# HC32M441 register map
File version: 1.0
CPU: CM4 r0p1, little endian, MPU, FPU, 4 interrupt priority bits
Registers are 32-bit, read-write, reset 0x0 unless marked. A register's access mark holds for its fields unless they carry their own. Offsets are from the block's base; [hi:lo] are bit positions; {n}, {i} and the like mark numbered series.

## I2C1 — desc I2C
Base 0x4003B400
Same registers: I2C2 0x4003B800
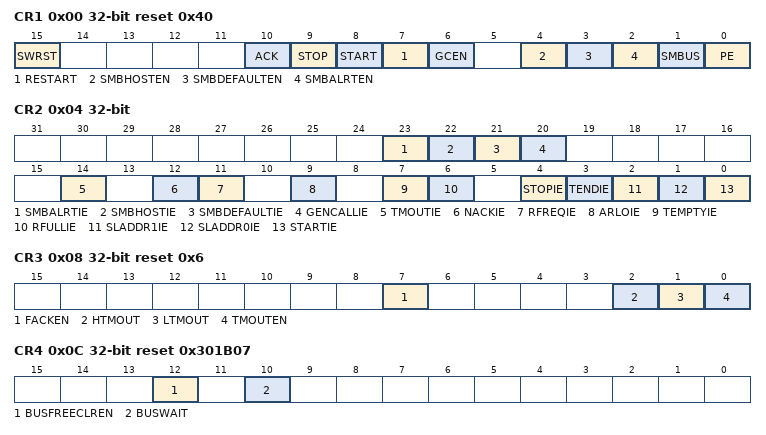
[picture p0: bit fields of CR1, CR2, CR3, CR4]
0x00 CR1 reset 0x40
  [15] SWRST, [10] ACK, [9] STOP, [8] START, [7] RESTART, [6] GCEN, [4] SMBHOSTEN, [3] SMBDEFAULTEN, [2] SMBALRTEN, [1] SMBUS, [0] PE
0x04 CR2
  [23] SMBALRTIE, [22] SMBHOSTIE, [21] SMBDEFAULTIE, [20] GENCALLIE, [14] TMOUTIE, [12] NACKIE, [11] RFREQIE, [9] ARLOIE, [7] TEMPTYIE, [6] RFULLIE, [4] STOPIE, [3] TENDIE, [2] SLADDR1IE, [1] SLADDR0IE, [0] STARTIE
0x08 CR3 reset 0x6
  [7] FACKEN, [2] HTMOUT, [1] LTMOUT, [0] TMOUTEN
0x0C CR4 reset 0x301B07
  [12] BUSFREECLREN, [10] BUSWAIT
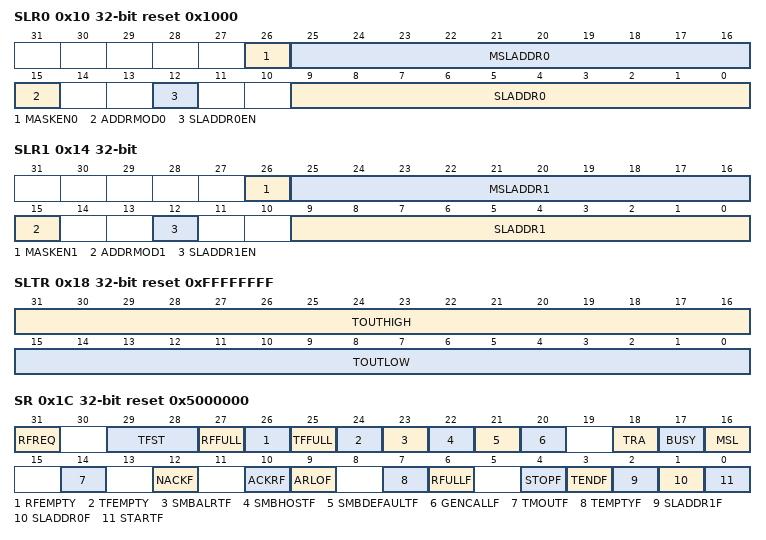
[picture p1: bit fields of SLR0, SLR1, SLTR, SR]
0x10 SLR0 reset 0x1000
  [26] MASKEN0, [25:16] MSLADDR0, [15] ADDRMOD0, [12] SLADDR0EN, [9:0] SLADDR0
0x14 SLR1
  [26] MASKEN1, [25:16] MSLADDR1, [15] ADDRMOD1, [12] SLADDR1EN, [9:0] SLADDR1
0x18 SLTR reset 0xFFFFFFFF
  [31:16] TOUTHIGH, [15:0] TOUTLOW
0x1C SR reset 0x5000000
  [31] RFREQ, [29:28] TFST, [27] RFFULL, [26] RFEMPTY, [25] TFFULL, [24] TFEMPTY, [23] SMBALRTF, [22] SMBHOSTF, [21] SMBDEFAULTF, [20] GENCALLF, [18] TRA, [17] BUSY, [16] MSL, [14] TMOUTF, [12] NACKF, [10] ACKRF, [9] ARLOF, [7] TEMPTYF, [6] RFULLF, [4] STOPF, [3] TENDF, [2] SLADDR1F, [1] SLADDR0F, [0] STARTF
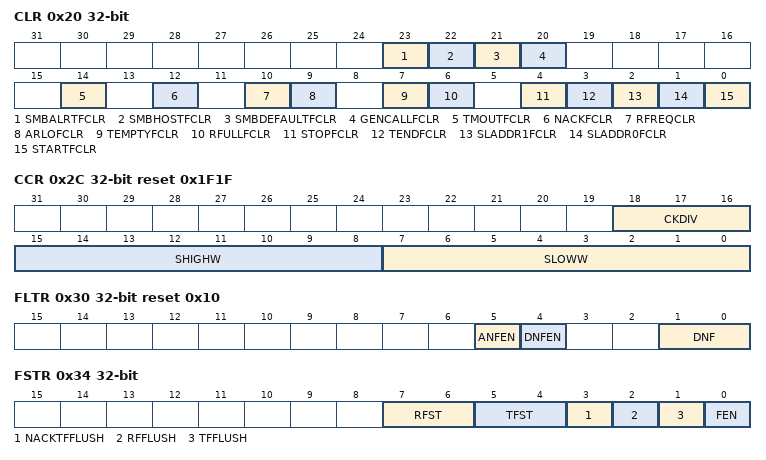
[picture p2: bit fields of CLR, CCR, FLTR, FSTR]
0x20 CLR wo
  [23] SMBALRTFCLR, [22] SMBHOSTFCLR, [21] SMBDEFAULTFCLR, [20] GENCALLFCLR, [14] TMOUTFCLR, [12] NACKFCLR, [10] RFREQCLR, [9] ARLOFCLR, [7] TEMPTYFCLR, [6] RFULLFCLR, [4] STOPFCLR, [3] TENDFCLR, [2] SLADDR1FCLR, [1] SLADDR0FCLR, [0] STARTFCLR
0x24 DTR 8-bit wo reset 0xFF
  [7:0] DT
0x28 DRR 8-bit ro
  [7:0] DR
0x2C CCR reset 0x1F1F
  [18:16] CKDIV, [15:8] SHIGHW, [7:0] SLOWW
0x30 FLTR reset 0x10
  [5] ANFEN, [4] DNFEN, [1:0] DNF
0x34 FSTR
  [7:6] RFST, [5:4] TFST, [3] NACKTFFLUSH, [2] RFFLUSH, [1] TFFLUSH, [0] FEN
0x38 SLVADDR
  [9:0] SLVADRR

## ICG
Base 0x00000400
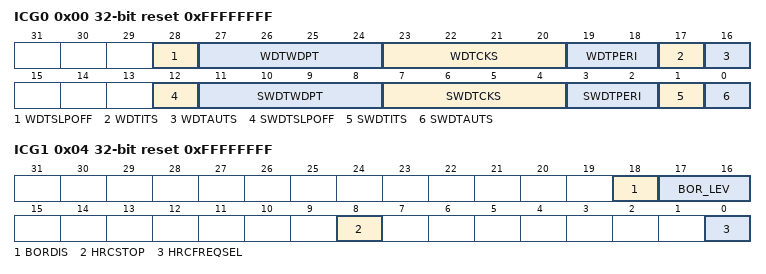
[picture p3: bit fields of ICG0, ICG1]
0x00 ICG0 ro reset 0xFFFFFFFF
  [28] WDTSLPOFF, [27:24] WDTWDPT, [23:20] WDTCKS, [19:18] WDTPERI, [17] WDTITS, [16] WDTAUTS, [12] SWDTSLPOFF, [11:8] SWDTWDPT, [7:4] SWDTCKS, [3:2] SWDTPERI, [1] SWDTITS, [0] SWDTAUTS
0x04 ICG1 ro reset 0xFFFFFFFF
  [18] BORDIS, [17:16] BOR_LEV, [8] HRCSTOP, [0] HRCFREQSEL
0x0C ICG3 ro reset 0xFFFFFFFF
  [15:0] DBUSPRT
0x10 ICG4 ro reset 0xFFFFFFFF

## INTC
Base 0x40051000
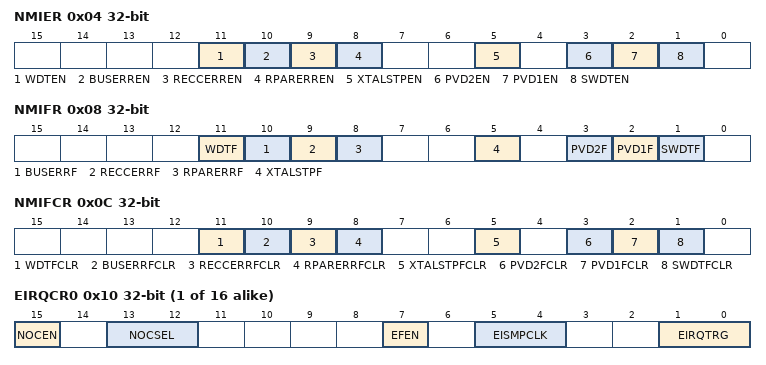
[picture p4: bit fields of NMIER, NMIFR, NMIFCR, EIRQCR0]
0x04 NMIER
  [11] WDTEN, [10] BUSERREN, [9] RECCERREN, [8] RPARERREN, [5] XTALSTPEN, [3] PVD2EN, [2] PVD1EN, [1] SWDTEN
0x08 NMIFR
  [11] WDTF, [10] BUSERRF, [9] RECCERRF, [8] RPARERRF, [5] XTALSTPF, [3] PVD2F, [2] PVD1F, [1] SWDTF
0x0C NMIFCR
  [11] WDTFCLR, [10] BUSERRFCLR, [9] RECCERRFCLR, [8] RPARERRFCLR, [5] XTALSTPFCLR, [3] PVD2FCLR, [2] PVD1FCLR, [1] SWDTFCLR
{0x10+4i} EIRQCR{i} (i=0..15)
  [15] NOCEN, [13:12] NOCSEL, [7] EFEN, [5:4] EISMPCLK, [1:0] EIRQTRG
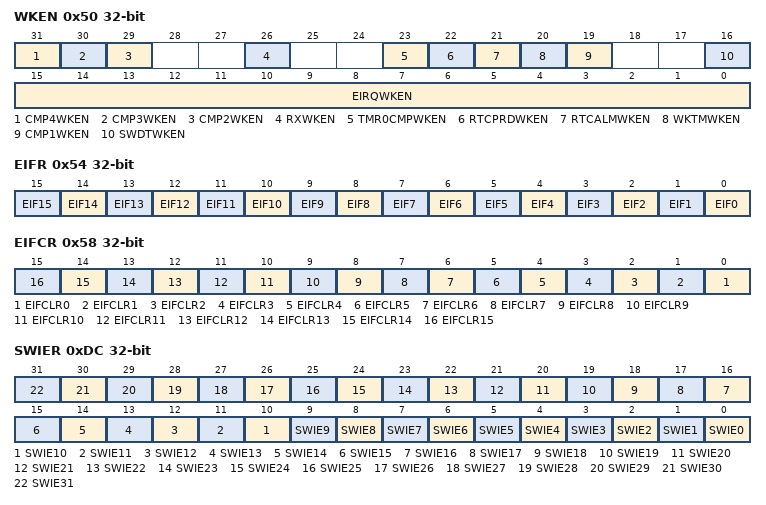
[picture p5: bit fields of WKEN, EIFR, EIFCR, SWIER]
0x50 WKEN
  [31] CMP4WKEN, [30] CMP3WKEN, [29] CMP2WKEN, [26] RXWKEN, [23] TMR0CMPWKEN, [22] RTCPRDWKEN, [21] RTCALMWKEN, [20] WKTMWKEN, [19] CMP1WKEN, [16] SWDTWKEN, [15:0] EIRQWKEN
0x54 EIFR
  [n] EIF{n} (n=0..15)
0x58 EIFCR
  [n] EIFCLR{n} (n=0..15)
{0x5C+4i} INTSEL{i} reset 0x1FF (i=0..15)
  [8:0] INTSEL
{0x9C+4i} INTEN{i} reset 0xFFFFFFFF (i=0..15)
  [31:0] INTEN
0xDC SWIER
  [n] SWIE{n} (n=0..31)
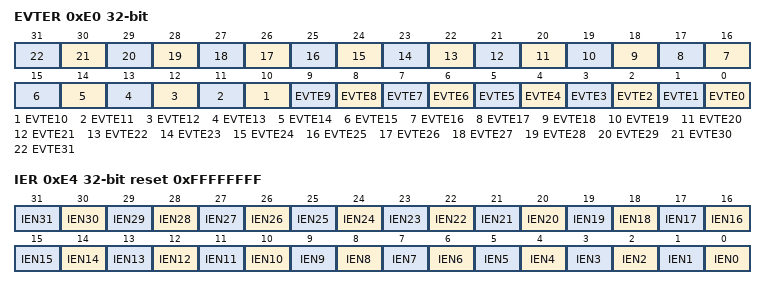
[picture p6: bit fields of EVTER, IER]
0xE0 EVTER
  [n] EVTE{n} (n=0..31)
0xE4 IER reset 0xFFFFFFFF
  [n] IEN{n} (n=0..31)

## KEYSCAN
Base 0x40050C00
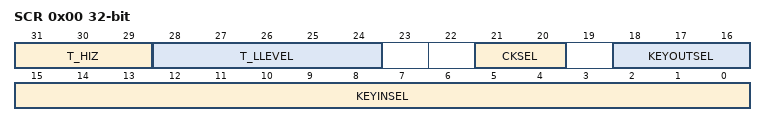
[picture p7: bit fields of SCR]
0x00 SCR
  [31:29] T_HIZ, [28:24] T_LLEVEL, [21:20] CKSEL, [18:16] KEYOUTSEL, [15:0] KEYINSEL
0x04 SER
  [0] SEN
0x08 SSR
  [2:0] INDEX

## MPU
Base 0x40050000
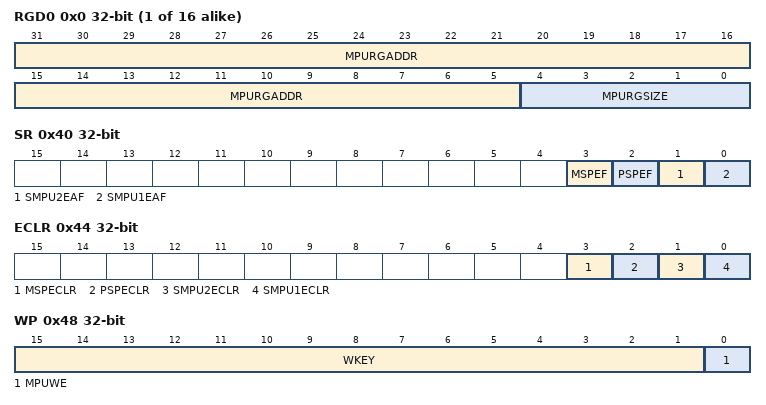
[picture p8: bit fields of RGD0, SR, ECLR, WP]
{0x0+4i} RGD{i} (i=0..15)
  [31:5] MPURGADDR, [4:0] MPURGSIZE
0x40 SR ro
  [3] MSPEF, [2] PSPEF, [1] SMPU2EAF, [0] SMPU1EAF
0x44 ECLR wo
  [3] MSPECLR, [2] PSPECLR, [1] SMPU2ECLR, [0] SMPU1ECLR
0x48 WP
  [15:1] WKEY, [0] MPUWE
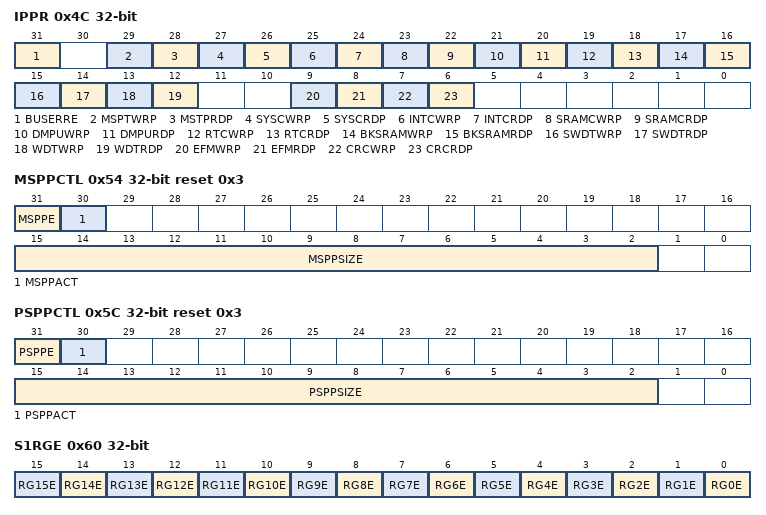
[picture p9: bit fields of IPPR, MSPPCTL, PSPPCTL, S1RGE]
0x4C IPPR (reset mask 0xBFFFF3A0)
  [31] BUSERRE, [29] MSPTWRP, [28] MSTPRDP, [27] SYSCWRP, [26] SYSCRDP, [25] INTCWRP, [24] INTCRDP, [23] SRAMCWRP, [22] SRAMCRDP, [21] DMPUWRP, [20] DMPURDP, [19] RTCWRP, [18] RTCRDP, [17] BKSRAMWRP, [16] BKSRAMRDP, [15] SWDTWRP, [14] SWDTRDP, [13] WDTWRP, [12] WDTRDP, [9] EFMWRP, [8] EFMRDP, [7] CRCWRP, [6] CRCRDP
0x50 MSPPBA
  [31:2] MSPPBA
0x54 MSPPCTL reset 0x3
  [31] MSPPE, [30] MSPPACT, [15:2] MSPPSIZE
0x58 PSPPBA
  [31:2] PSPPBA
0x5C PSPPCTL reset 0x3
  [31] PSPPE, [30] PSPPACT, [15:2] PSPPSIZE
0x60 S1RGE
  [n] RG{n}E (n=0..15)
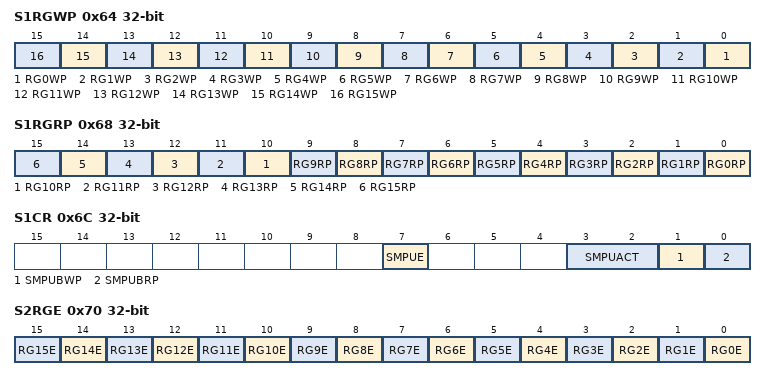
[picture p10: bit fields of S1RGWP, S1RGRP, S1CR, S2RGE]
0x64 S1RGWP
  [n] RG{n}WP (n=0..15)
0x68 S1RGRP
  [n] RG{n}RP (n=0..15)
0x6C S1CR
  [7] SMPUE, [3:2] SMPUACT, [1] SMPUBWP, [0] SMPUBRP
0x70 S2RGE
  [n] RG{n}E (n=0..15)
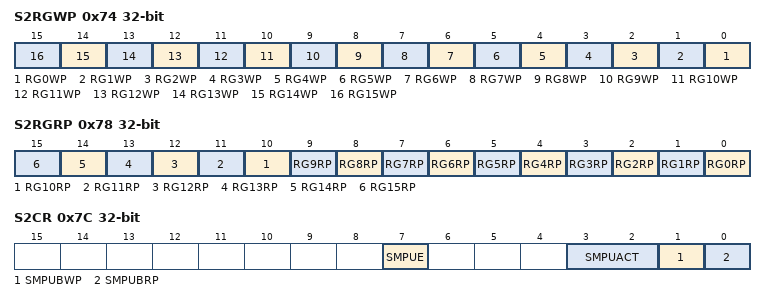
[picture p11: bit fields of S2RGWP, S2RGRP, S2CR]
0x74 S2RGWP
  [n] RG{n}WP (n=0..15)
0x78 S2RGRP
  [n] RG{n}RP (n=0..15)
0x7C S2CR
  [7] SMPUE, [3:2] SMPUACT, [1] SMPUBWP, [0] SMPUBRP
